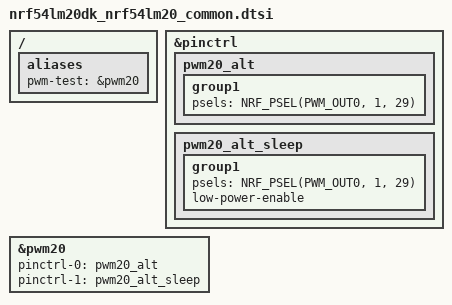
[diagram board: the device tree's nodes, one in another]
/*
 * Copyright (c) 2026 Nordic Semiconductor ASA
 * SPDX-License-Identifier: Apache-2.0
 */

/ {
	aliases {
		pwm-test = &pwm20;
	};
};

&pinctrl {
	pwm20_alt: pwm20_alt {
		group1 {
			psels = <NRF_PSEL(PWM_OUT0, 1, 29)>;
		};
	};

	pwm20_alt_sleep: pwm20_alt_sleep {
		group1 {
			psels = <NRF_PSEL(PWM_OUT0, 1, 29)>;
			low-power-enable;
		};
	};
};

&pwm20 {
	status = "okay";
	pinctrl-0 = <&pwm20_alt>;
	pinctrl-1 = <&pwm20_alt_sleep>;
	pinctrl-names = "default", "sleep";
};
